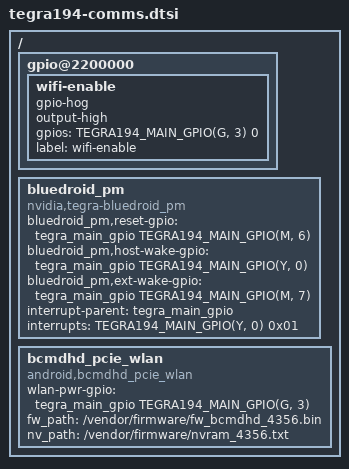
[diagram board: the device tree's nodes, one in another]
/*
 * Copyright (c) 2017, NVIDIA CORPORATION.  All rights reserved.
 *
 * This program is free software; you can redistribute it and/or modify
 * it under the terms of the GNU General Public License as published by
 * the Free Software Foundation; version 2 of the License.
 *
 * This program is distributed in the hope that it will be useful, but WITHOUT
 * ANY WARRANTY; without even the implied warranty of MERCHANTABILITY or
 * FITNESS FOR A PARTICULAR PURPOSE.  See the GNU General Public License for
 * more details.
 *
 * You should have received a copy of the GNU General Public License along
 * with this program; if not, write to the Free Software Foundation, Inc.,
 * 51 Franklin Street, Fifth Floor, Boston, MA  02110-1301, USA.
 *
 */
#include <dt-bindings/gpio/tegra194-gpio.h>

/ {
	/* Need to enable wifi_en pin during boot for PCIe enumeration */
	gpio@2200000 {
		wifi-enable {
			gpio-hog;
			output-high;
			gpios = <TEGRA194_MAIN_GPIO(G, 3) 0>;
			label = "wifi-enable";
			status = "okay";
		};
	};

	bluedroid_pm {
		compatible = "nvidia,tegra-bluedroid_pm";
		bluedroid_pm,reset-gpio = <&tegra_main_gpio TEGRA194_MAIN_GPIO(M, 6) 0>;
		bluedroid_pm,host-wake-gpio = <&tegra_main_gpio TEGRA194_MAIN_GPIO(Y, 0) 0>;
		bluedroid_pm,ext-wake-gpio = <&tegra_main_gpio TEGRA194_MAIN_GPIO(M, 7) 0>;
		interrupt-parent = <&tegra_main_gpio>;
		interrupts = <TEGRA194_MAIN_GPIO(Y, 0) 0x01>;
	};

	bcmdhd_pcie_wlan {
		compatible = "android,bcmdhd_pcie_wlan";
		wlan-pwr-gpio = <&tegra_main_gpio TEGRA194_MAIN_GPIO(G, 3) 0>;
		fw_path = "/vendor/firmware/fw_bcmdhd_4356.bin";
		nv_path = "/vendor/firmware/nvram_4356.txt";
		status = "okay";
	};
};
